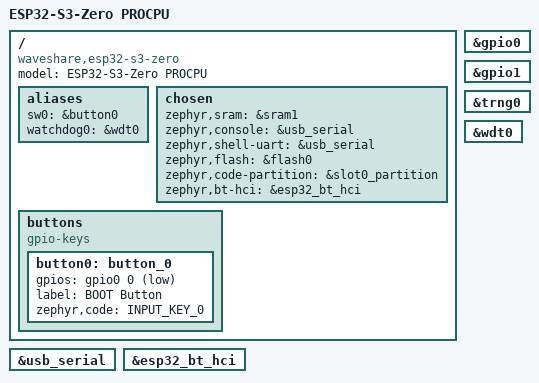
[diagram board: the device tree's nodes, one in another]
/*
 * Copyright (c) 2024 Joel Guittet
 * Copyright (c) 2025 Chen Xingyu <hi@xingrz.me>
 * Copyright (c) 2025 marrowbuster <info@marrowbuster.com>
 * SPDX-License-Identifier: Apache-2.0
 */

/dts-v1/;
#include <espressif/esp32s3/esp32s3_fh4r2.dtsi>
#include <espressif/partitions_0x0_amp_4M.dtsi>
#include <zephyr/dt-bindings/input/input-event-codes.h>

/ {
	model = "ESP32-S3-Zero PROCPU";
	compatible = "waveshare,esp32-s3-zero";

	aliases {
		sw0 = &button0;
		watchdog0 = &wdt0;
	};

	chosen {
		zephyr,sram = &sram1;
		zephyr,console = &usb_serial;
		zephyr,shell-uart = &usb_serial;
		zephyr,flash = &flash0;
		zephyr,code-partition = &slot0_partition;
		zephyr,bt-hci = &esp32_bt_hci;
	};

	buttons {
		compatible = "gpio-keys";

		button0: button_0 {
			gpios = <&gpio0 0 (GPIO_PULL_UP | GPIO_ACTIVE_LOW)>;
			label = "BOOT Button";
			zephyr,code = <INPUT_KEY_0>;
		};
	};
};

&gpio0 {
	status = "okay";
};

&gpio1 {
	status = "okay";
};


&usb_serial {
	status = "okay";
};

&trng0 {
	status = "okay";
};

&wdt0 {
	status = "okay";
};

&esp32_bt_hci {
	status = "okay";
};
